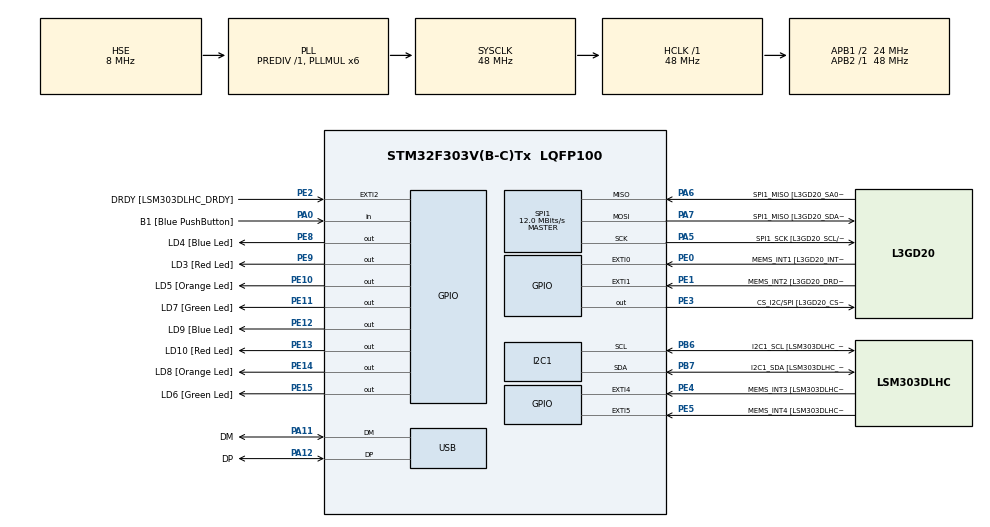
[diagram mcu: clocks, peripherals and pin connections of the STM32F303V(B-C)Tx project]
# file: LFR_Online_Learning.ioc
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Mcu.Family=STM32F3
PA6.Mode=Full_Duplex_Master
RCC.CortexFreq_Value=48000000
SPI1.VirtualType=VM_MASTER
PE11.GPIO_Label=LD7 [Green Led]
PA14.GPIO_Label=SWCLK
RCC.SYSCLKSourceVirtual=RCC_SYSCLKSOURCE_PLLCLK
PA0.GPIO_Label=B1 [Blue PushButton]
PA11.Mode=Device
PA6.GPIO_Label=SPI1_MISO [L3GD20_SA0/SDO]
PB6.GPIO_Label=I2C1_SCL [LSM303DLHC_SCL]
PC15-OSC32_OUT.GPIO_Label=OSC32_OUT
ProjectManager.StackSize=0x400
SPI1.Mode-Full_Duplex_Master=SPI_MODE_MASTER
PA12.Signal=USB_DP
SPI1.Direction=SPI_DIRECTION_2LINES
RCC.HCLKFreq_Value=48000000
RCC.APB2TimFreq_Value=48000000
PB6.Signal=I2C1_SCL
PB6.Mode=I2C
SPI1.CalculateBaudRate=12.0 MBits/s
PE5.Signal=GPXTI5
PE1.Signal=GPXTI1
RCC.AHBFreq_Value=48000000
RCC.HSE_VALUE=8000000
PF0-OSC_IN.GPIO_Label=OSC_IN
RCC.PLLMUL=RCC_PLL_MUL6
PE13.Signal=GPIO_Output
PE9.Signal=GPIO_Output
PA14.Mode=Serial_Wire
PE4.GPIO_Label=MEMS_INT3 [LSM303DLHC_INT1]
PE2.Signal=GPXTI2
PB7.Signal=I2C1_SDA
PE10.Signal=GPIO_Output
PE4.Signal=GPXTI4
SPI1.CalculateBaudRate-Full_Duplex_Master=24.0 MBits/s
PA0.Signal=GPIO_Input
PB7.GPIO_Label=I2C1_SDA [LSM303DLHC_SDA]
Mcu.Package=LQFP100
PA6.Signal=SPI1_MISO
PE12.GPIO_Label=LD9 [Blue Led]
PE0.GPIO_Label=MEMS_INT1 [L3GD20_INT1]
RCC.APB1TimFreq_Value=48000000
PC14-OSC32_IN.GPIO_Label=OSC32_IN
PE10.GPIO_Label=LD5 [Orange Led]
SPI1.BaudRatePrescaler=SPI_BAUDRATEPRESCALER_4
PE2.GPIO_Label=DRDY [LSM303DLHC_DRDY]
PF1-OSC_OUT.Signal=RCC_OSC_OUT
PA5.Mode=Full_Duplex_Master
PB3.GPIO_Label=SWO
PA7.Mode=Full_Duplex_Master
PE4.GPIO_ModeDefaultEXTI=GPIO_MODE_EVT_RISING
PA11.GPIO_Label=DM
PE14.GPIO_Label=LD8 [Orange Led]
PE1.GPIO_ModeDefaultEXTI=GPIO_MODE_EVT_RISING
RCC.APB1CLKDivider=RCC_HCLK_DIV2
PC14-OSC32_IN.Signal=RCC_OSC32_IN
PA12.GPIO_Label=DP
PA13.Signal=SYS_JTMS-SWDIO
PE15.GPIO_Label=LD6 [Green Led]
ProjectManager.TargetToolchain=STM32CubeIDE
PE5.GPIO_ModeDefaultEXTI=GPIO_MODE_EVT_RISING
PE0.GPIO_ModeDefaultEXTI=GPIO_MODE_EVT_RISING
PE8.GPIO_Label=LD4 [Blue Led]
I2C1.Timing=0x2000090E
RCC.USBFreq_Value=48000000
PE11.Signal=GPIO_Output
RCC.LSE_VALUE=32768
PC15-OSC32_OUT.Signal=RCC_OSC32_OUT
PE9.GPIO_Label=LD3 [Red Led]
PF0-OSC_IN.Mode=HSE-External-Clock-Source
PA5.Signal=SPI1_SCK
board=STM32F3DISCOVERY
PE1.GPIO_Label=MEMS_INT2 [L3GD20_DRDY/INT2]
RCC.APB2Freq_Value=48000000
PE14.Signal=GPIO_Output
PE15.Signal=GPIO_Output
PE8.Signal=GPIO_Output
SPI1.Mode=SPI_MODE_MASTER
PF1-OSC_OUT.GPIO_Label=OSC_OUT
I2C1.Timing-I2C=0x2000090E
PA13.Mode=Serial_Wire
Mcu.Name=STM32F303V(B-C)Tx
PE0.Signal=GPXTI0
PE12.Signal=GPIO_Output
PA13.GPIO_Label=SWDIO
PB3.Signal=SYS_JTDO-TRACESWO
RCC.SYSCLKFreq_VALUE=48000000
PA7.GPIO_Label=SPI1_MISO [L3GD20_SDA/SDI/SDO]
PE13.GPIO_Label=LD10 [Red Led]
PA12.Mode=Device
PA5.GPIO_Label=SPI1_SCK [L3GD20_SCL/SPC]
PE5.GPIO_Label=MEMS_INT4 [LSM303DLHC_INT2]
PB7.Mode=I2C
PA11.Signal=USB_DM
PA14.Signal=SYS_JTCK-SWCLK
ProjectManager.HeapSize=0x200
RCC.HSI_VALUE=8000000
NVIC.PriorityGroup=NVIC_PRIORITYGROUP_0
PE3.Signal=GPIO_Output
PE3.GPIO_Label=CS_I2C/SPI [L3GD20_CS_I2C/SPI]
PE2.GPIO_ModeDefaultEXTI=GPIO_MODE_EVT_RISING
PF0-OSC_IN.Signal=RCC_OSC_IN
RCC.APB1Freq_Value=24000000
SPI1.BaudRatePrescaler-Full_Duplex_Master=SPI_BAUDRATEPRESCALER_2
PA7.Signal=SPI1_MOSI

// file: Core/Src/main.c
/* USER CODE BEGIN Header */
/**
  ******************************************************************************
  * @file           : main.c
  * @brief          : Main program body
  ******************************************************************************
  * @attention
  *
  * <h2><center>&copy; Copyright (c) 2021 STMicroelectronics.
  * All rights reserved.</center></h2>
  *
  * This software component is licensed by ST under BSD 3-Clause license,
  * the "License"; You may not use this file except in compliance with the
  * License. You may obtain a copy of the License at:
  *                        opensource.org/licenses/BSD-3-Clause
  *
  ******************************************************************************
  */
/* USER CODE END Header */
#include "main.h"

/* USER CODE BEGIN Includes */
#include <stdio.h>
#include "FreeRTOS.h"
#include "task.h"
/* USER CODE END Includes */

I2C_HandleTypeDef hi2c1;

SPI_HandleTypeDef hspi1;

PCD_HandleTypeDef hpcd_USB_FS;

/* USER CODE BEGIN PV */
#define DWT_CTRL		(*(volatile uint32_t*)0xE0001000)
/* USER CODE END PV */

void SystemClock_Config(void);
static void MX_GPIO_Init(void);
static void MX_I2C1_Init(void);
static void MX_SPI1_Init(void);
static void MX_USB_PCD_Init(void);

int main(void)
{

  /* MCU Configuration--------------------------------------------------------*/

  /* Reset of all peripherals, Initializes the Flash interface and the Systick. */
  HAL_Init();

  /* Configure the system clock */
  SystemClock_Config();

  /* Initialize all configured peripherals */
  MX_GPIO_Init();
  MX_I2C1_Init();
  MX_SPI1_Init();
  MX_USB_PCD_Init();
  /* USER CODE BEGIN 2 */
  DWT_CTRL |= (1 << 0);
  /* USER CODE END 2 */

  /* Infinite loop */
  while (1)
  {

  }
}

void SystemClock_Config(void)
{
  RCC_OscInitTypeDef RCC_OscInitStruct = {0};
  RCC_ClkInitTypeDef RCC_ClkInitStruct = {0};
  RCC_PeriphCLKInitTypeDef PeriphClkInit = {0};

  /** Initializes the RCC Oscillators according to the specified parameters
  * in the RCC_OscInitTypeDef structure.
  */
  RCC_OscInitStruct.OscillatorType = RCC_OSCILLATORTYPE_HSI|RCC_OSCILLATORTYPE_HSE;
  RCC_OscInitStruct.HSEState = RCC_HSE_BYPASS;
  RCC_OscInitStruct.HSEPredivValue = RCC_HSE_PREDIV_DIV1;
  RCC_OscInitStruct.HSIState = RCC_HSI_ON;
  RCC_OscInitStruct.HSICalibrationValue = RCC_HSICALIBRATION_DEFAULT;
  RCC_OscInitStruct.PLL.PLLState = RCC_PLL_ON;
  RCC_OscInitStruct.PLL.PLLSource = RCC_PLLSOURCE_HSE;
  RCC_OscInitStruct.PLL.PLLMUL = RCC_PLL_MUL6;
  if (HAL_RCC_OscConfig(&RCC_OscInitStruct) != HAL_OK)
  {
    Error_Handler();
  }
  /** Initializes the CPU, AHB and APB buses clocks
  */
  RCC_ClkInitStruct.ClockType = RCC_CLOCKTYPE_HCLK|RCC_CLOCKTYPE_SYSCLK
                              |RCC_CLOCKTYPE_PCLK1|RCC_CLOCKTYPE_PCLK2;
  RCC_ClkInitStruct.SYSCLKSource = RCC_SYSCLKSOURCE_PLLCLK;
  RCC_ClkInitStruct.AHBCLKDivider = RCC_SYSCLK_DIV1;
  RCC_ClkInitStruct.APB1CLKDivider = RCC_HCLK_DIV2;
  RCC_ClkInitStruct.APB2CLKDivider = RCC_HCLK_DIV1;

  if (HAL_RCC_ClockConfig(&RCC_ClkInitStruct, FLASH_LATENCY_1) != HAL_OK)
  {
    Error_Handler();
  }
  PeriphClkInit.PeriphClockSelection = RCC_PERIPHCLK_USB|RCC_PERIPHCLK_I2C1;
  PeriphClkInit.I2c1ClockSelection = RCC_I2C1CLKSOURCE_HSI;
  PeriphClkInit.USBClockSelection = RCC_USBCLKSOURCE_PLL;
  if (HAL_RCCEx_PeriphCLKConfig(&PeriphClkInit) != HAL_OK)
  {
    Error_Handler();
  }
}

static void MX_I2C1_Init(void)
{

  hi2c1.Instance = I2C1;
  hi2c1.Init.Timing = 0x2000090E;
  hi2c1.Init.OwnAddress1 = 0;
  hi2c1.Init.AddressingMode = I2C_ADDRESSINGMODE_7BIT;
  hi2c1.Init.DualAddressMode = I2C_DUALADDRESS_DISABLE;
  hi2c1.Init.OwnAddress2 = 0;
  hi2c1.Init.OwnAddress2Masks = I2C_OA2_NOMASK;
  hi2c1.Init.GeneralCallMode = I2C_GENERALCALL_DISABLE;
  hi2c1.Init.NoStretchMode = I2C_NOSTRETCH_DISABLE;
  if (HAL_I2C_Init(&hi2c1) != HAL_OK)
  {
    Error_Handler();
  }
  /** Configure Analogue filter
  */
  if (HAL_I2CEx_ConfigAnalogFilter(&hi2c1, I2C_ANALOGFILTER_ENABLE) != HAL_OK)
  {
    Error_Handler();
  }
  /** Configure Digital filter
  */
  if (HAL_I2CEx_ConfigDigitalFilter(&hi2c1, 0) != HAL_OK)
  {
    Error_Handler();
  }

}

static void MX_SPI1_Init(void)
{

  /* SPI1 parameter configuration*/
  hspi1.Instance = SPI1;
  hspi1.Init.Mode = SPI_MODE_MASTER;
  hspi1.Init.Direction = SPI_DIRECTION_2LINES;
  hspi1.Init.DataSize = SPI_DATASIZE_4BIT;
  hspi1.Init.CLKPolarity = SPI_POLARITY_LOW;
  hspi1.Init.CLKPhase = SPI_PHASE_1EDGE;
  hspi1.Init.NSS = SPI_NSS_SOFT;
  hspi1.Init.BaudRatePrescaler = SPI_BAUDRATEPRESCALER_4;
  hspi1.Init.FirstBit = SPI_FIRSTBIT_MSB;
  hspi1.Init.TIMode = SPI_TIMODE_DISABLE;
  hspi1.Init.CRCCalculation = SPI_CRCCALCULATION_DISABLE;
  hspi1.Init.CRCPolynomial = 7;
  hspi1.Init.CRCLength = SPI_CRC_LENGTH_DATASIZE;
  hspi1.Init.NSSPMode = SPI_NSS_PULSE_ENABLE;
  if (HAL_SPI_Init(&hspi1) != HAL_OK)
  {
    Error_Handler();
  }

}

static void MX_USB_PCD_Init(void)
{

  hpcd_USB_FS.Instance = USB;
  hpcd_USB_FS.Init.dev_endpoints = 8;
  hpcd_USB_FS.Init.speed = PCD_SPEED_FULL;
  hpcd_USB_FS.Init.phy_itface = PCD_PHY_EMBEDDED;
  hpcd_USB_FS.Init.low_power_enable = DISABLE;
  hpcd_USB_FS.Init.battery_charging_enable = DISABLE;
  if (HAL_PCD_Init(&hpcd_USB_FS) != HAL_OK)
  {
    Error_Handler();
  }

}

static void MX_GPIO_Init(void)
{
  GPIO_InitTypeDef GPIO_InitStruct = {0};

  /* GPIO Ports Clock Enable */
  __HAL_RCC_GPIOE_CLK_ENABLE();
  __HAL_RCC_GPIOC_CLK_ENABLE();
  __HAL_RCC_GPIOF_CLK_ENABLE();
  __HAL_RCC_GPIOA_CLK_ENABLE();
  __HAL_RCC_GPIOB_CLK_ENABLE();

  /*Configure GPIO pin Output Level */
  HAL_GPIO_WritePin(GPIOE, CS_I2C_SPI_Pin|LD4_Pin|LD3_Pin|LD5_Pin
                          |LD7_Pin|LD9_Pin|LD10_Pin|LD8_Pin
                          |LD6_Pin, GPIO_PIN_RESET);

  /*Configure GPIO pins : DRDY_Pin MEMS_INT3_Pin MEMS_INT4_Pin MEMS_INT1_Pin
                           MEMS_INT2_Pin */
  GPIO_InitStruct.Pin = DRDY_Pin|MEMS_INT3_Pin|MEMS_INT4_Pin|MEMS_INT1_Pin
                          |MEMS_INT2_Pin;
  GPIO_InitStruct.Mode = GPIO_MODE_EVT_RISING;
  GPIO_InitStruct.Pull = GPIO_NOPULL;
  HAL_GPIO_Init(GPIOE, &GPIO_InitStruct);

  /*Configure GPIO pins : CS_I2C_SPI_Pin LD4_Pin LD3_Pin LD5_Pin
                           LD7_Pin LD9_Pin LD10_Pin LD8_Pin
                           LD6_Pin */
  GPIO_InitStruct.Pin = CS_I2C_SPI_Pin|LD4_Pin|LD3_Pin|LD5_Pin
                          |LD7_Pin|LD9_Pin|LD10_Pin|LD8_Pin
                          |LD6_Pin;
  GPIO_InitStruct.Mode = GPIO_MODE_OUTPUT_PP;
  GPIO_InitStruct.Pull = GPIO_NOPULL;
  GPIO_InitStruct.Speed = GPIO_SPEED_FREQ_LOW;
  HAL_GPIO_Init(GPIOE, &GPIO_InitStruct);

  /*Configure GPIO pin : B1_Pin */
  GPIO_InitStruct.Pin = B1_Pin;
  GPIO_InitStruct.Mode = GPIO_MODE_INPUT;
  GPIO_InitStruct.Pull = GPIO_NOPULL;
  HAL_GPIO_Init(B1_GPIO_Port, &GPIO_InitStruct);

}

void Error_Handler(void)
{
  __disable_irq();
  while (1)
  {
  }
}

/************************ (C) COPYRIGHT STMicroelectronics *****END OF FILE****/
